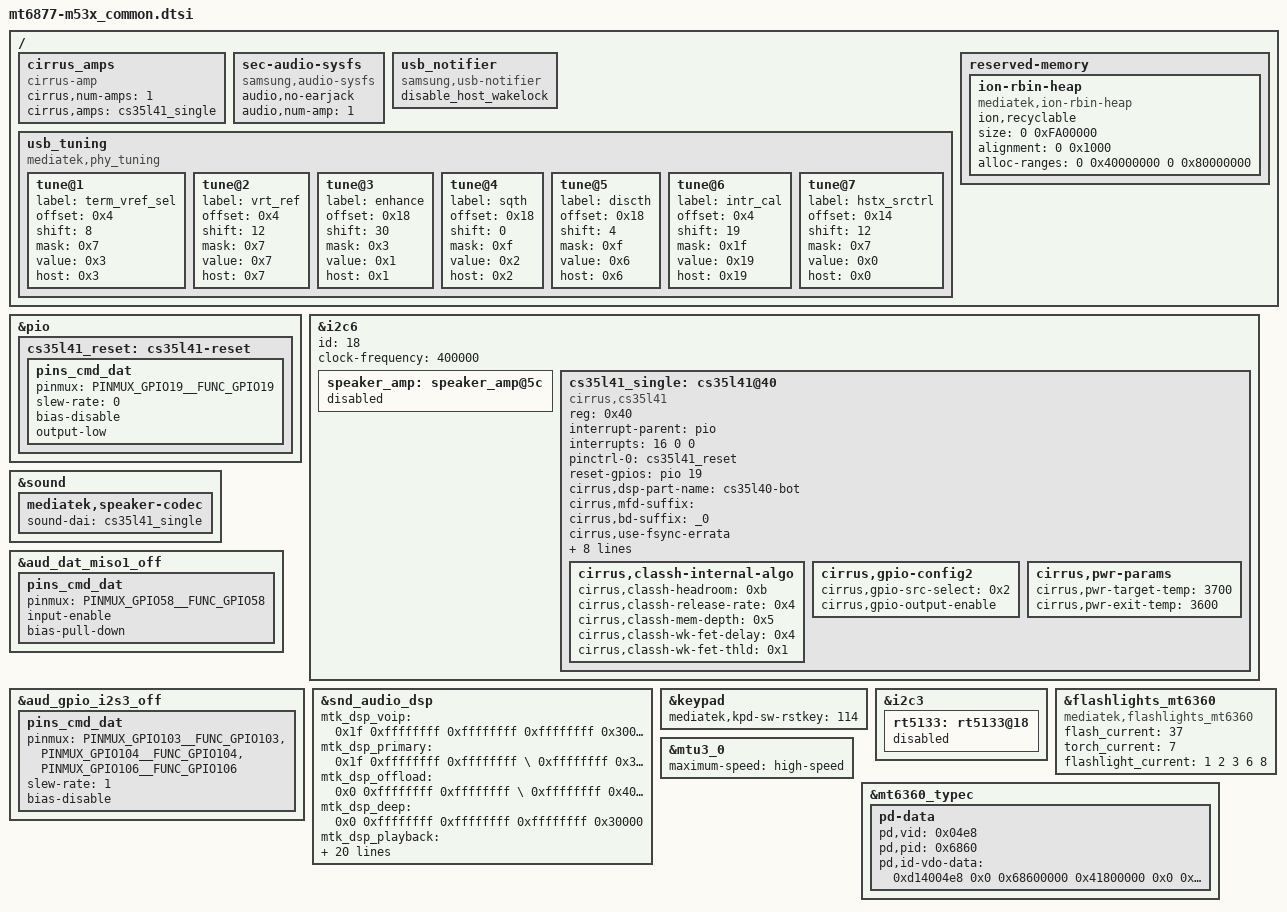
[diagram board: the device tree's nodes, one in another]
/* Generated by Samsung for MTK vendor board
 * If these files should be changed, then please make a sync with MTK
*/

/* Add Samsung configuration over here */
#include "display_lcd_m53x_common.dtsi"

/ {
	fragment@model {
		target-path = "/";
		__overlay__ {

			cirrus_amps {
				compatible = "cirrus-amp";
				cirrus,num-amps = <1>;
				cirrus,amps = <&cs35l41_single>;
			};

			sec-audio-sysfs {
				compatible = "samsung,audio-sysfs";
				status = "okay";
				audio,no-earjack;
				audio,num-amp = <1>;
			};

			usb_notifier {
				compatible = "samsung,usb-notifier";
				disable_host_wakelock;
			};

			usb_tuning:usb_tuning {
				compatible = "mediatek,phy_tuning";

				tune@1 {
					label = "term_vref_sel";
					offset = <0x4>;
					shift = <8>;
					mask = <0x7>;
					value = <0x3>;
					host = <0x3>;
				};

				tune@2 {
					label = "vrt_ref";
					offset = <0x4>;
					shift = <12>;
					mask = <0x7>;
					value = <0x7>;
					host = <0x7>;
				};

				tune@3 {
					label = "enhance";
					offset = <0x18>;
					shift = <30>;
					mask = <0x3>;
					value = <0x1>;
					host = <0x1>;
				};

				tune@4 {
					label = "sqth";
					offset = <0x18>;
					shift = <0>;
					mask = <0xf>;
					value = <0x2>;
					host = <0x2>;
				};

				tune@5 {
					label = "discth";
					offset = <0x18>;
					shift = <4>;
					mask = <0xf>;
					value = <0x6>;
					host = <0x6>;
				};

				tune@6 {
					label = "intr_cal";
					offset = <0x4>;
					shift = <19>;
					mask = <0x1f>;
					value = <0x19>;
					host = <0x19>;
				};

				tune@7 {
					label = "hstx_srctrl";
					offset = <0x14>;
					shift = <12>;
					mask = <0x7>;
					value = <0x0>;
					host = <0x0>;
				};
			};

			reserved-memory {
				ion-rbin-heap {
					compatible = "mediatek,ion-rbin-heap";
					ion,recyclable;
					size = <0 0xFA00000>;
					alignment = <0 0x1000>;
					alloc-ranges = <0 0x40000000 0 0x80000000>;
				};
			};	
		};
	};
};
&pio {
	cs35l41_reset: cs35l41-reset {
		pins_cmd_dat {
			pinmux = <PINMUX_GPIO19__FUNC_GPIO19>;
			slew-rate = <0>;
			bias-disable;
			output-low;
		};
	};
};
&i2c6 {
	speaker_amp: speaker_amp@5c {
		status = "disabled";
	};
};

&i2c6 {
	status = "okay";
	id = <18>;
	clock-frequency = <400000>;
	#address-cells = <1>;
	#size-cells = <0>;

	cs35l41_single: cs35l41@40 {
		#sound-dai-cells = <0>;
		compatible = "cirrus,cs35l41";
		reg = <0x40>;
		interrupt-parent = <&pio>;
		interrupts = <16 0 0>;
		pinctrl-names = "default";
		pinctrl-0 = <&cs35l41_reset>;
		reset-gpios = <&pio 19 0>;
		//VA-supply = <&l2_reg>;
		//VP-supply = <&vbat>;

		cirrus,dsp-part-name = "cs35l40-bot";
		cirrus,mfd-suffix = "";
		cirrus,bd-suffix = "_0";
		cirrus,use-fsync-errata;
		cirrus,bd-max-temp = <110>;

		//cirrus,asp-sdout-hiz = <0x3>;

		cirrus,dsp-noise-gate-enable;
		cirrus,dsp-noise-gate-delay = <0x4>;
		cirrus,dsp-noise-gate-threshold = <0x6>;

		cirrus,hw-noise-gate-select = <0x3F>;
		cirrus,hw-noise-gate-delay = <0x4>;
		cirrus,hw-noise-gate-threshold = <0x6>;

		cirrus,boost-peak-milliamp = <4100>;

		cirrus,classh-internal-algo {
			cirrus,classh-headroom = <0xb>;
			cirrus,classh-release-rate = <0x4>;
			cirrus,classh-mem-depth = <0x5>;
			cirrus,classh-wk-fet-delay = <0x4>;
			cirrus,classh-wk-fet-thld = <0x1>;
		};

		cirrus,gpio-config2 {
			cirrus,gpio-src-select = <0x2>;
			cirrus,gpio-output-enable;
		};

		cirrus,pwr-params {
			/* cirrus,pwr-global-enable; */
			cirrus,pwr-target-temp = <3700>;
			cirrus,pwr-exit-temp = <3600>;
		};
	};
};

&sound {
	mediatek,speaker-codec {
		sound-dai = <&cs35l41_single>;
	};
};

&aud_dat_miso1_off {
	pins_cmd_dat {
		pinmux = <PINMUX_GPIO58__FUNC_GPIO58>;
		input-enable;
		bias-pull-down;
	};
};

&aud_gpio_i2s3_off {
	pins_cmd_dat {
		pinmux = <PINMUX_GPIO103__FUNC_GPIO103>,
			 <PINMUX_GPIO104__FUNC_GPIO104>,
			 <PINMUX_GPIO106__FUNC_GPIO106>;
		slew-rate = <1>;
		bias-disable;
	};
};

&snd_audio_dsp {
	mtk_dsp_voip = <0x1f 0xffffffff 0xffffffff 0xffffffff 0x30000>;
	mtk_dsp_primary = <0x1f 0xffffffff 0xffffffff \
				0xffffffff 0x30000>;
	mtk_dsp_offload = <0x0 0xffffffff 0xffffffff \
				0xffffffff 0x400000>;
	mtk_dsp_deep = <0x0 0xffffffff 0xffffffff 0xffffffff 0x30000>;
	mtk_dsp_playback = <0x1 0x4 0xffffffff 0x14 0x30000>;
	mtk_dsp_music = <0x1 0xffffffff 0xffffffff 0xffffffff 0x0>;
	mtk_dsp_capture1 = <0x1 0xffffffff 0xd 0x13 0x20000>;
	mtk_dsp_a2dp = <0x1 0xffffffff 0xffffffff 0xffffffff 0x40000>;
	mtk_dsp_dataprovider = <0x0 0xffffffff 0xf 0xffffffff 0x30000>;
	mtk_dsp_call_final = <0x0 0x4 0x10 0x14 0x18000>;
	mtk_dsp_fast = <0x5 0xffffffff 0xffffffff 0xffffffff 0x5000>;
	mtk_dsp_ktv = <0x1 0x8 0x12 0xffffffff 0x10000>;
	mtk_dsp_capture_raw = <0x0 0xffffffff 0xffffffff 0xffffffff 0x20000>;
	mtk_dsp_fm = <0x1 0xffffffff 0x10 0xffffffff 0x10000>;
	mtk_dsp_ver = <0x1>;
	swdsp_smartpa_process_enable = <0x0>;
	mtk_dsp_mem_afe = <0x1 0x40000>; /* always enable */
};

&keypad {
	mediatek,kpd-sw-rstkey  = <114>;
};

&i2c3 {
	rt5133: rt5133@18 {
		status = "disabled";
	};
};


&flashlights_mt6360 {
	compatible = "mediatek,flashlights_mt6360";
	flash_current = <37>;
	torch_current = <7>;
	flashlight_current = <1 2 3 6 8>;
};

&mtu3_0 {
	maximum-speed = "high-speed";
};

&mt6360_typec {
	pd-data {
		pd,vid = <0x04e8>;
		pd,pid = <0x6860>;
		pd,id-vdo-data = <0xd14004e8 0x0 0x68600000
				 0x41800000 0x0 0x21800000>;
	};
};
